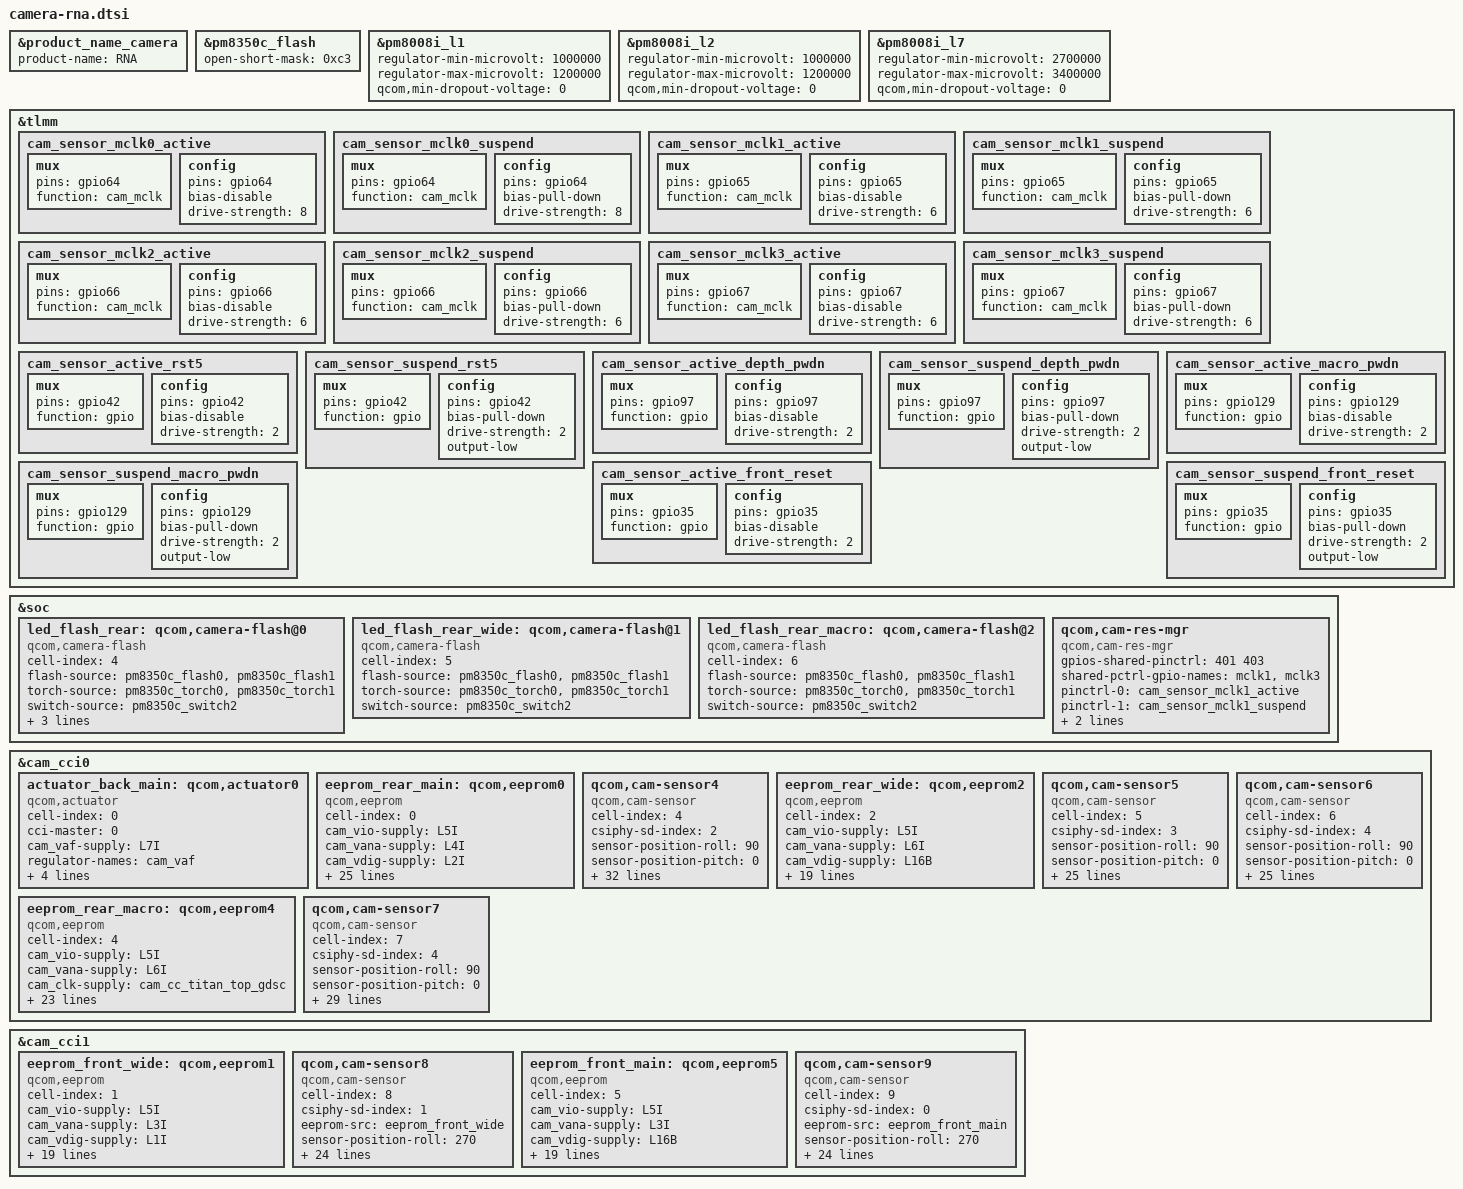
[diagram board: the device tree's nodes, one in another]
#include <dt-bindings/clock/qcom,camcc-yupik.h>
#include "../isolate-qrd.dtsi"

&product_name_camera {
	product-name = "RNA";
};

&pm8350c_flash {
	open-short-mask = /bits/ 8 <0xc3>;
};

&pm8008i_l1 {
	regulator-min-microvolt = <1000000>;
	regulator-max-microvolt = <1200000>;
	qcom,min-dropout-voltage = <0>;
};

&pm8008i_l2 {
	regulator-min-microvolt = <1000000>;
	regulator-max-microvolt = <1200000>;
	qcom,min-dropout-voltage = <0>;
};

&pm8008i_l7 {
	regulator-min-microvolt = <2700000>;
	regulator-max-microvolt = <3400000>;
	qcom,min-dropout-voltage = <0>;
};

&tlmm {
	cam_sensor_mclk0_active: cam_sensor_mclk0_active {
		/* MCLK0 */
		mux {
			pins = "gpio64";
			function = "cam_mclk";
		};

		config {
			pins = "gpio64";
			bias-disable; /* No PULL */
			drive-strength = <8>; /* 8 MA */
		};
	};

	cam_sensor_mclk0_suspend: cam_sensor_mclk0_suspend {
		/* MCLK0 */
		mux {
			pins = "gpio64";
			function = "cam_mclk";
		};

		config {
			pins = "gpio64";
			bias-pull-down; /* PULL DOWN */
			drive-strength = <8>; /* 8 MA */
		};
	};

	cam_sensor_mclk1_active: cam_sensor_mclk1_active {
		/* MCLK1 */
		mux {
			pins = "gpio65";
			function = "cam_mclk";
		};

		config {
			pins = "gpio65";
			bias-disable; /* No PULL */
			drive-strength = <6>; /* 6 MA */
		};
	};

	cam_sensor_mclk1_suspend: cam_sensor_mclk1_suspend {
		/* MCLK1 */
		mux {
			pins = "gpio65";
			function = "cam_mclk";
		};

		config {
			pins = "gpio65";
			bias-pull-down; /* PULL DOWN */
			drive-strength = <6>; /* 6 MA */
		};
	};

	cam_sensor_mclk2_active: cam_sensor_mclk2_active {
		/* MCLK2 */
		mux {
			pins = "gpio66";
			function = "cam_mclk";
		};

		config {
			pins = "gpio66";
			bias-disable; /* No PULL */
			drive-strength = <6>; /* 6 MA */
		};
	};

	cam_sensor_mclk2_suspend: cam_sensor_mclk2_suspend {
		/* MCLK2 */
		mux {
			pins = "gpio66";
			function = "cam_mclk";
		};

		config {
			pins = "gpio66";
			bias-pull-down; /* PULL DOWN */
			drive-strength = <6>; /* 6 MA */
		};
	};

	cam_sensor_mclk3_active: cam_sensor_mclk3_active {
		/* MCLK3 */
		mux {
			pins = "gpio67";
			function = "cam_mclk";
		};

		config {
			pins = "gpio67";
			bias-disable; /* No PULL */
			drive-strength = <6>; /* 6 MA */
		};
	};

	cam_sensor_mclk3_suspend: cam_sensor_mclk3_suspend {
		/* MCLK3 */
		mux {
			pins = "gpio67";
			function = "cam_mclk";
		};

		config {
			pins = "gpio67";
			bias-pull-down; /* PULL DOWN */
			drive-strength = <6>; /* 6 MA */
		};
	};

	cam_sensor_active_rst5: cam_sensor_active_rst5 {
		/* RESET 5 */
		mux {
			pins = "gpio42";
			function = "gpio";
		};

		config {
			pins = "gpio42";
			bias-disable; /* No PULL */
			drive-strength = <2>; /* 2 MA */
		};
	};

	cam_sensor_suspend_rst5: cam_sensor_suspend_rst5 {
		/* RESET 5 */
		mux {
			pins = "gpio42";
			function = "gpio";
		};

		config {
			pins = "gpio42";
			bias-pull-down; /* PULL DOWN */
			drive-strength = <2>; /* 2 MA */
			output-low;
		};
	};

	cam_sensor_active_depth_pwdn: cam_sensor_active_depth_pwdn {
		/* pwdn enable */
		mux {
			pins = "gpio97";
			function = "gpio";
		};

		config {
			pins = "gpio97";
			bias-disable; /* No PULL */
			drive-strength = <2>; /* 2 MA */
		};
	};

	cam_sensor_suspend_depth_pwdn: cam_sensor_suspend_depth_pwdn {
		/* pwdn disable */
		mux {
			pins = "gpio97";
			function = "gpio";
		};

		config {
			pins = "gpio97";
			bias-pull-down; /* PULL DOWN */
			drive-strength = <2>; /* 2 MA */
			output-low;
		};
	};

	cam_sensor_active_macro_pwdn: cam_sensor_active_macro_pwdn {
		/* pwdn enable */
		mux {
			pins = "gpio129";
			function = "gpio";
		};

		config {
			pins = "gpio129";
			bias-disable; /* No PULL */
			drive-strength = <2>; /* 2 MA */
		};
	};

	cam_sensor_suspend_macro_pwdn: cam_sensor_suspend_macro_pwdn {
		/* pwdn disable */
		mux {
			pins = "gpio129";
			function = "gpio";
		};

		config {
			pins = "gpio129";
			bias-pull-down; /* PULL DOWN */
			drive-strength = <2>; /* 2 MA */
			output-low;
		};
	};

	cam_sensor_active_front_reset: cam_sensor_active_front_reset {
		/* reset enable */
		mux {
			pins = "gpio35";
			function = "gpio";
		};

		config {
			pins = "gpio35";
			bias-disable; /* No PULL */
			drive-strength = <2>; /* 2 MA */
		};
	};

	cam_sensor_suspend_front_reset: cam_sensor_suspend_front_reset {
		/* reset disable */
		mux {
			pins = "gpio35";
			function = "gpio";
		};

		config {
			pins = "gpio35";
			bias-pull-down; /* PULL DOWN */
			drive-strength = <2>; /* 2 MA */
			output-low;
		};
	};
};

&soc {
	led_flash_rear: qcom,camera-flash@0 {
		cell-index = <4>;
		compatible = "qcom,camera-flash";
		flash-source = <&pm8350c_flash0 &pm8350c_flash1>;
		torch-source = <&pm8350c_torch0 &pm8350c_torch1>;
		switch-source = <&pm8350c_switch2>;
		torch-light-num = <0>;
		torch-light-name = "torch-light0";
		flash_thermal;
		status = "ok";
	};

	led_flash_rear_wide: qcom,camera-flash@1 {
		cell-index = <5>;
		compatible = "qcom,camera-flash";
		flash-source = <&pm8350c_flash0 &pm8350c_flash1>;
		torch-source = <&pm8350c_torch0 &pm8350c_torch1>;
		switch-source = <&pm8350c_switch2>;
		status = "ok";
	};

	led_flash_rear_macro: qcom,camera-flash@2 {
		cell-index = <6>;
		compatible = "qcom,camera-flash";
		flash-source = <&pm8350c_flash0 &pm8350c_flash1>;
		torch-source = <&pm8350c_torch0 &pm8350c_torch1>;
		switch-source = <&pm8350c_switch2>;
		status = "ok";
	};

	qcom,cam-res-mgr {
		compatible = "qcom,cam-res-mgr";
		gpios-shared-pinctrl = <401 403>; /* 65 + 336 = 401, 67 + 336 = 403 */
		shared-pctrl-gpio-names = "mclk1", "mclk3";
		pinctrl-names = "mclk1_active", "mclk1_suspend", "mclk3_active", "mclk3_suspend";
		pinctrl-0 = <&cam_sensor_mclk1_active>;
		pinctrl-1 = <&cam_sensor_mclk1_suspend>;
		pinctrl-2 = <&cam_sensor_mclk3_active>;
		pinctrl-3 = <&cam_sensor_mclk3_suspend>;
		status = "ok";
	};
};

&cam_cci0 {
	actuator_back_main: qcom,actuator0 {
		cell-index = <0>;
		compatible = "qcom,actuator";
		cci-master = <0>;
		cam_vaf-supply = <&L7I>;
		regulator-names = "cam_vaf";
		rgltr-cntrl-support;
		rgltr-min-voltage = <3200000>;
		rgltr-max-voltage = <3200000>;
		rgltr-load-current = <2000000>;
	};

	eeprom_rear_main: qcom,eeprom0 {
		cell-index = <0>;
		compatible = "qcom,eeprom";
		cam_vio-supply = <&L5I>;
		cam_vana-supply = <&L4I>;
		cam_vdig-supply = <&L2I>;
		cam_v_custom1-supply = <&L7I>;
		cam_clk-supply = <&cam_cc_titan_top_gdsc>;
		regulator-names = "cam_vio", "cam_vana", "cam_vdig",
			"cam_v_custom1", "cam_clk";
		rgltr-cntrl-support;
		rgltr-min-voltage = <1800000 2800000 1135000 3200000 0>;
		rgltr-max-voltage = <1800000 2900000 1135000 3200000 0>;
		rgltr-load-current = <10000 52000 140000 2000000 0>;
		gpio-no-mux = <0>;
		pinctrl-names = "cam_default", "cam_suspend";
		pinctrl-0 = <&cam_sensor_mclk0_active
			&cam_sensor_active_rst0>;
		pinctrl-1 = <&cam_sensor_mclk0_suspend
			&cam_sensor_suspend_rst0>;
		gpios = <&tlmm 64 0>,
			<&tlmm 20 0>;
		gpio-reset = <1>;
		gpio-req-tbl-num = <0 1>;
		gpio-req-tbl-flags = <1 0>;
		gpio-req-tbl-label = "CAMIF_MCLK0",
			"CAM_RESET0";
		cci-master = <0>;
		status = "ok";
		clocks = <&camcc CAM_CC_MCLK0_CLK>;
		clock-names = "cam_clk";
		clock-cntl-level = "nominal";
		clock-rates = <24000000>;
	};

	/* Rear (Main) */
	qcom,cam-sensor4 {
		cell-index = <4>;
		compatible = "qcom,cam-sensor";
		csiphy-sd-index = <2>;
		sensor-position-roll = <90>;
		sensor-position-pitch = <0>;
		sensor-position-yaw = <180>;
		eeprom-src = <&eeprom_rear_main>;
		actuator-src = <&actuator_back_main>;
		led-flash-src = <&led_flash_rear>;
		cam_vio-supply = <&L5I>;
		cam_vana-supply = <&L4I>;
		cam_vdig-supply = <&L2I>;
		cam_v_custom1-supply = <&L7I>;
		cam_clk-supply = <&cam_cc_titan_top_gdsc>;
		regulator-names = "cam_vio", "cam_vana", "cam_vdig",
			"cam_v_custom1", "cam_clk";
		rgltr-cntrl-support;
		rgltr-min-voltage = <1800000 2800000 1135000 3200000 0>;
		rgltr-max-voltage = <1800000 2900000 1135000 3200000 0>;
		rgltr-load-current = <10000 52000 140000 2000000 0>;
		gpio-no-mux = <0>;
		pinctrl-names = "cam_default", "cam_suspend";
		pinctrl-0 = <&cam_sensor_mclk0_active
			&cam_sensor_active_rst0>;
		pinctrl-1 = <&cam_sensor_mclk0_suspend
			&cam_sensor_suspend_rst0>;
		gpios = <&tlmm 64 0>,
			<&tlmm 20 0>;
		gpio-reset = <1>;
		gpio-req-tbl-num = <0 1>;
		gpio-req-tbl-flags = <1 0>;
		gpio-req-tbl-label = "CAMIF_MCLK0",
			"CAM_RESET0";
		cci-master = <0>;
		status = "ok";
		clocks = <&camcc CAM_CC_MCLK0_CLK>;
		clock-names = "cam_clk";
		clock-cntl-level = "nominal";
		clock-rates = <24000000>;
	};

	eeprom_rear_wide: qcom,eeprom2 {
		cell-index = <2>;
		compatible = "qcom,eeprom";
		cam_vio-supply = <&L5I>;
		cam_vana-supply = <&L6I>;
		cam_vdig-supply = <&L16B>;
		cam_clk-supply = <&cam_cc_titan_top_gdsc>;
		regulator-names = "cam_vio", "cam_vana",
			"cam_vdig","cam_clk";
		rgltr-cntrl-support;
		rgltr-min-voltage = <1800000 2850000 1104000 0>;
		rgltr-max-voltage = <1800000 2900000 1200000 0>;
		rgltr-load-current = <5000 68000 805000 0>;
		gpio-no-mux = <0>;
		pinctrl-names = "cam_default", "cam_suspend";
		pinctrl-0 = <&cam_sensor_active_rst1>;
		pinctrl-1 = <&cam_sensor_suspend_rst1>;
		gpios = <&tlmm 65 0>,
			<&tlmm 21 0>;
		gpio-reset = <1>;
		gpio-req-tbl-num = <0 1>;
		gpio-req-tbl-flags = <1 0>;
		gpio-req-tbl-label = "CAMIF_MCLK1",
			"CAM_RESET1";
		cci-master = <1>;
		status = "ok";
		clocks = <&camcc CAM_CC_MCLK1_CLK>;
		clock-names = "cam_clk";
		clock-cntl-level = "nominal";
		clock-rates = <24000000>;
	};

	/* Rear (Wide) */
	qcom,cam-sensor5 {
		cell-index = <5>;
		compatible = "qcom,cam-sensor";
		csiphy-sd-index = <3>;
		sensor-position-roll = <90>;
		sensor-position-pitch = <0>;
		sensor-position-yaw = <180>;
		eeprom-src = <&eeprom_rear_wide>;
		led-flash-src = <&led_flash_rear_wide>;
		cam_vio-supply = <&L5I>;
		cam_vana-supply = <&L6I>;
		cam_vdig-supply = <&L16B>;
		cam_clk-supply = <&cam_cc_titan_top_gdsc>;
		regulator-names = "cam_vio", "cam_vana",
			"cam_vdig","cam_clk";
		rgltr-cntrl-support;
		rgltr-min-voltage = <1800000 2850000 1104000 0>;
		rgltr-max-voltage = <1800000 2900000 1200000 0>;
		rgltr-load-current = <5000 68000 805000 0>;
		gpio-no-mux = <0>;
		pinctrl-names = "cam_default", "cam_suspend";
		pinctrl-0 = <&cam_sensor_active_rst1>;
		pinctrl-1 = <&cam_sensor_suspend_rst1>;
		gpios = <&tlmm 65 0>,
			<&tlmm 21 0>;
		gpio-reset = <1>;
		gpio-req-tbl-num = <0 1>;
		gpio-req-tbl-flags = <1 0>;
		gpio-req-tbl-label = "CAMIF_MCLK1",
			"CAM_RESET1";
		cci-master = <1>;
		status = "ok";
		clocks = <&camcc CAM_CC_MCLK1_CLK>;
		clock-names = "cam_clk";
		clock-cntl-level = "nominal";
		clock-rates = <24000000>;
	};

	/* Rear (Depth) */
	qcom,cam-sensor6 {
		cell-index = <6>;
		compatible = "qcom,cam-sensor";
		csiphy-sd-index = <4>;
		sensor-position-roll = <90>;
		sensor-position-pitch = <0>;
		sensor-position-yaw = <180>;
		cam_vio-supply = <&L5I>;
		cam_vana-supply = <&L6I>;
		cam_clk-supply = <&cam_cc_titan_top_gdsc>;
		regulator-names = "cam_vio", "cam_vana","cam_clk";
		rgltr-cntrl-support;
		rgltr-min-voltage = <1800000 2850000 0>;
		rgltr-max-voltage = <1800000 2900000 0>;
		rgltr-load-current = <5000 68000 0>;
		gpio-no-mux = <0>;
		pinctrl-names = "cam_default", "cam_suspend";
		pinctrl-0 = <&cam_sensor_active_rst2
			&cam_sensor_active_depth_pwdn>;
		pinctrl-1 = <&cam_sensor_suspend_rst2
			&cam_sensor_suspend_depth_pwdn>;
		gpios = <&tlmm 65 0>,
			<&tlmm 77 0>,
			<&tlmm 97 0>;
		gpio-reset = <1>;
		gpio-custom1 = <2>;
		gpio-req-tbl-num = <0 1 2>;
		gpio-req-tbl-flags = <1 0 0>;
		gpio-req-tbl-label = "CAMIF_MCLK1",
			"CAM_RESET2",
			"CAM_CUSTOM1";
		cci-master = <1>;
		status = "ok";
		clocks = <&camcc CAM_CC_MCLK1_CLK>;
		clock-names = "cam_clk";
		clock-cntl-level = "nominal";
		clock-rates = <24000000>;
	};

	eeprom_rear_macro: qcom,eeprom4 {
		cell-index = <4>;
		compatible = "qcom,eeprom";
		cam_vio-supply = <&L5I>;
		cam_vana-supply = <&L6I>;
		cam_clk-supply = <&cam_cc_titan_top_gdsc>;
		regulator-names = "cam_vio", "cam_vana",
			"cam_clk";
		rgltr-cntrl-support;
		rgltr-min-voltage = <1800000 2800000 0>;
		rgltr-max-voltage = <1800000 2900000 0>;
		rgltr-load-current = <3000 52000 0>;
		gpio-no-mux = <0>;
		pinctrl-names = "cam_default", "cam_suspend";
		pinctrl-0 = <&cam_sensor_mclk2_active
			&cam_sensor_active_rst5
			&cam_sensor_active_macro_pwdn>;
		pinctrl-1 = <&cam_sensor_mclk2_suspend
			&cam_sensor_suspend_rst5
			&cam_sensor_suspend_macro_pwdn>;
		gpios = <&tlmm 66 0>,
			<&tlmm 42 0>,
			<&tlmm 129 0>;
		gpio-reset = <1>;
		gpio-custom1 = <2>;
		gpio-req-tbl-num = <0 1 2>;
		gpio-req-tbl-flags = <1 0 0>;
		gpio-req-tbl-label = "CAMIF_MCLK2",
			"CAM_RESET5",
			"CAM_CUSTOM1";
		cci-master = <0>;
		status = "ok";
		clocks = <&camcc CAM_CC_MCLK2_CLK>;
		clock-names = "cam_clk";
		clock-cntl-level = "nominal";
		clock-rates = <24000000>;
	};

	/* Rear (Macro) */
	qcom,cam-sensor7 {
		cell-index = <7>;
		compatible = "qcom,cam-sensor";
		csiphy-sd-index = <4>;
		sensor-position-roll = <90>;
		sensor-position-pitch = <0>;
		sensor-position-yaw = <180>;
		eeprom-src = <&eeprom_rear_macro>;
		led-flash-src = <&led_flash_rear_macro>;
		cam_vio-supply = <&L5I>;
		cam_vana-supply = <&L6I>;
		cam_clk-supply = <&cam_cc_titan_top_gdsc>;
		regulator-names = "cam_vio", "cam_vana",
			"cam_clk";
		rgltr-cntrl-support;
		rgltr-min-voltage = <1800000 2800000 0>;
		rgltr-max-voltage = <1800000 2900000 0>;
		rgltr-load-current = <3000 52000 0>;
		gpio-no-mux = <0>;
		pinctrl-names = "cam_default", "cam_suspend";
		pinctrl-0 = <&cam_sensor_mclk2_active
			&cam_sensor_active_rst5
			&cam_sensor_active_macro_pwdn>;
		pinctrl-1 = <&cam_sensor_mclk2_suspend
			&cam_sensor_suspend_rst5
			&cam_sensor_suspend_macro_pwdn>;
		gpios = <&tlmm 66 0>,
			<&tlmm 42 0>,
			<&tlmm 129 0>;
		gpio-reset = <1>;
		gpio-custom1 = <2>;
		gpio-req-tbl-num = <0 1 2>;
		gpio-req-tbl-flags = <1 0 0>;
		gpio-req-tbl-label = "CAMIF_MCLK2",
			"CAM_RESET5",
			"CAM_CUSTOM1";
		cci-master = <0>;
		status = "ok";
		clocks = <&camcc CAM_CC_MCLK2_CLK>;
		clock-names = "cam_clk";
		clock-cntl-level = "nominal";
		clock-rates = <24000000>;
	};
};

&cam_cci1 {
	eeprom_front_wide: qcom,eeprom1 {
		cell-index = <1>;
		compatible = "qcom,eeprom";
		cam_vio-supply = <&L5I>;
		cam_vana-supply = <&L3I>;
		cam_vdig-supply = <&L1I>;
		cam_clk-supply = <&cam_cc_titan_top_gdsc>;
		regulator-names = "cam_vio", "cam_vana", "cam_vdig",
			"cam_clk";
		rgltr-cntrl-support;
		rgltr-min-voltage = <1800000 2800000 1100000 0>;
		rgltr-max-voltage = <1800000 2900000 1100000 0>;
		rgltr-load-current = <5000 35000 301000 0>;
		gpio-no-mux = <0>;
		pinctrl-names = "cam_default", "cam_suspend";
		pinctrl-0 = <&cam_sensor_active_rst3>;
		pinctrl-1 = <&cam_sensor_suspend_rst3>;
		gpios = <&tlmm 67 0>,
			<&tlmm 78 0>;
		gpio-reset = <1>;
		gpio-req-tbl-num = <0 1>;
		gpio-req-tbl-flags = <1 0>;
		gpio-req-tbl-label = "CAMIF_MCLK3",
			"CAM_RESET3";
		cci-master = <1>;
		status = "ok";
		clocks = <&camcc CAM_CC_MCLK3_CLK>;
		clock-names = "cam_clk";
		clock-cntl-level = "nominal";
		clock-rates = <24000000>;
	};

	/* Front 32M */
	qcom,cam-sensor8 {
		cell-index = <8>;
		compatible = "qcom,cam-sensor";
		csiphy-sd-index = <1>;
		eeprom-src = <&eeprom_front_wide>;
		sensor-position-roll = <270>;
		sensor-position-pitch = <0>;
		sensor-position-yaw = <0>;
		cam_vio-supply = <&L5I>;
		cam_vana-supply = <&L3I>;
		cam_vdig-supply = <&L1I>;
		cam_clk-supply = <&cam_cc_titan_top_gdsc>;
		regulator-names = "cam_vio", "cam_vana", "cam_vdig",
			"cam_clk";
		rgltr-cntrl-support;
		rgltr-min-voltage = <1800000 2800000 1100000 0>;
		rgltr-max-voltage = <1800000 2900000 1100000 0>;
		rgltr-load-current = <5000 35000 301000 0>;
		gpio-no-mux = <0>;
		pinctrl-names = "cam_default", "cam_suspend";
		pinctrl-0 = <&cam_sensor_active_rst3>;
		pinctrl-1 = <&cam_sensor_suspend_rst3>;
		gpios = <&tlmm 67 0>,
			<&tlmm 78 0>;
		gpio-reset = <1>;
		gpio-req-tbl-num = <0 1>;
		gpio-req-tbl-flags = <1 0>;
		gpio-req-tbl-label = "CAMIF_MCLK3",
			"CAM_RESET3";
		cci-master = <1>;
		status = "ok";
		clocks = <&camcc CAM_CC_MCLK3_CLK>;
		clock-names = "cam_clk";
		clock-cntl-level = "nominal";
		clock-rates = <24000000>;
	};

	eeprom_front_main: qcom,eeprom5 {
		cell-index = <5>;
		compatible = "qcom,eeprom";
		cam_vio-supply = <&L5I>;
		cam_vana-supply = <&L3I>;
		cam_vdig-supply = <&L16B>;
		cam_clk-supply = <&cam_cc_titan_top_gdsc>;
		regulator-names = "cam_vio", "cam_vana", "cam_vdig",
			"cam_clk";
		rgltr-cntrl-support;
		rgltr-min-voltage = <1800000 2800000 1056000 0>;
		rgltr-max-voltage = <1800000 2900000 1150000 0>;
		rgltr-load-current = <5000 35000 301000 0>;
		gpio-no-mux = <0>;
		pinctrl-names = "cam_default", "cam_suspend";
		pinctrl-0 = <&cam_sensor_active_front_reset>;
		pinctrl-1 = <&cam_sensor_suspend_front_reset>;
		gpios = <&tlmm 67 0>,
			<&tlmm 35 0>;
		gpio-reset = <1>;
		gpio-req-tbl-num = <0 1>;
		gpio-req-tbl-flags = <1 0>;
		gpio-req-tbl-label = "CAMIF_MCLK3",
			"CAM_RESET3";
		cci-master = <0>;
		status = "ok";
		clocks = <&camcc CAM_CC_MCLK3_CLK>;
		clock-names = "cam_clk";
		clock-cntl-level = "nominal";
		clock-rates = <24000000>;
	};

	/* Front 12M */
	qcom,cam-sensor9 {
		cell-index = <9>;
		compatible = "qcom,cam-sensor";
		csiphy-sd-index = <0>;
		eeprom-src = <&eeprom_front_main>;
		sensor-position-roll = <270>;
		sensor-position-pitch = <0>;
		sensor-position-yaw = <0>;
		cam_vio-supply = <&L5I>;
		cam_vana-supply = <&L3I>;
		cam_vdig-supply = <&L16B>;
		cam_clk-supply = <&cam_cc_titan_top_gdsc>;
		regulator-names = "cam_vio", "cam_vana", "cam_vdig",
			"cam_clk";
		rgltr-cntrl-support;
		rgltr-min-voltage = <1800000 2800000 1056000 0>;
		rgltr-max-voltage = <1800000 2900000 1150000 0>;
		rgltr-load-current = <5000 35000 301000 0>;
		gpio-no-mux = <0>;
		pinctrl-names = "cam_default", "cam_suspend";
		pinctrl-0 = <&cam_sensor_active_front_reset>;
		pinctrl-1 = <&cam_sensor_suspend_front_reset>;
		gpios = <&tlmm 67 0>,
			<&tlmm 35 0>;
		gpio-reset = <1>;
		gpio-req-tbl-num = <0 1>;
		gpio-req-tbl-flags = <1 0>;
		gpio-req-tbl-label = "CAMIF_MCLK3",
			"CAM_RESET3";
		cci-master = <0>;
		status = "ok";
		clocks = <&camcc CAM_CC_MCLK3_CLK>;
		clock-names = "cam_clk";
		clock-cntl-level = "nominal";
		clock-rates = <24000000>;
	};
};
